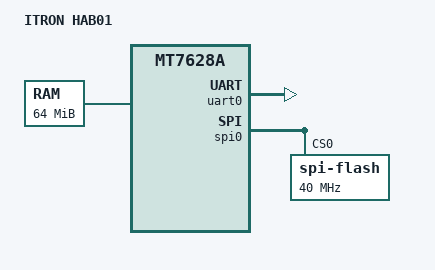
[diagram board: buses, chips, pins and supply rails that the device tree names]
// SPDX-License-Identifier: GPL-2.0
/*
 * Copyright (C) 2018 Stefan Roese <sr@denx.de>
 */

/dts-v1/;

#include "mt7628a.dtsi"

/ {
	compatible = "itron,itronhab01", "ralink,mt7628a-soc";
	model = "ITRON HAB01";

	aliases {
		serial0 = &uart0;
		spi0 = &spi0;
	};

	memory@0 {
		device_type = "memory";
		reg = <0x0 0x04000000>;
	};

	chosen {
		stdout-path = &uart0;
    bootargs = "console=ttyS0,57600";
	};
};

&uart0 {
	status = "okay";
	clock-frequency = <40000000>;
};

&spi0 {
	status = "okay";
	num-cs = <2>;

	spi-flash@0 {
		#address-cells = <1>;
		#size-cells = <1>;
		compatible = "spi-flash", "jedec,spi-nor";
		spi-max-frequency = <40000000>;
		reg = <0>;
	};
};
